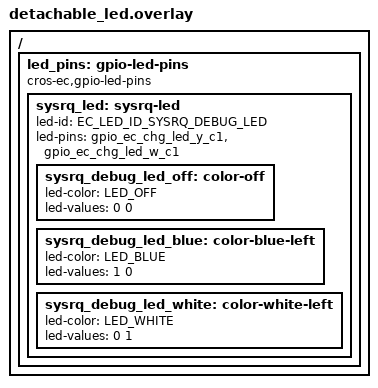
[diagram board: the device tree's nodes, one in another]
/* Copyright 2023 The ChromiumOS Authors
 * Use of this source code is governed by a BSD-style license that can be
 * found in the LICENSE file.
 */

/ {
	/delete-node/ pwm-led-pins;

	led_pins: gpio-led-pins {
		compatible = "cros-ec,gpio-led-pins";

		sysrq_led: sysrq-led {
			led-id = "EC_LED_ID_SYSRQ_DEBUG_LED";
			led-pins = <&gpio_ec_chg_led_y_c1
				    &gpio_ec_chg_led_w_c1>;

			sysrq_debug_led_off: color-off {
				led-color = "LED_OFF";
				led-values = <0 0>;
			};

			sysrq_debug_led_blue: color-blue-left {
				led-color = "LED_BLUE";
				led-values = <1 0>;
			};
			sysrq_debug_led_white: color-white-left {
				led-color = "LED_WHITE";
				led-values = <0 1>;
			};
		};
	};
};
